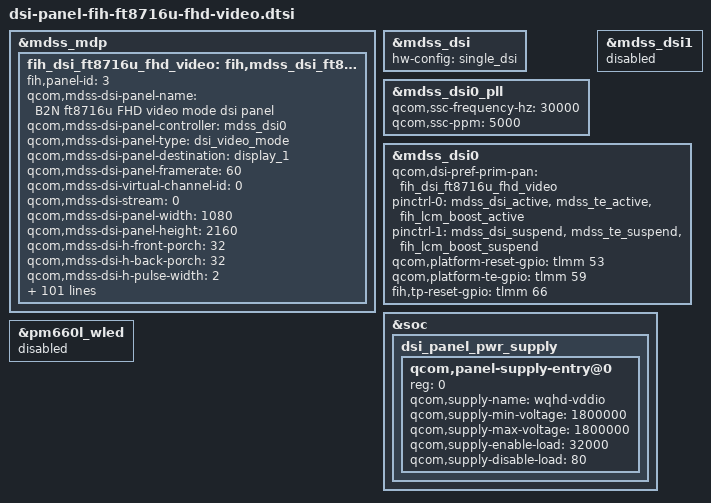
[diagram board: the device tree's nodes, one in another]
/* Copyright (c) 2013, The Linux Foundation. All rights reserved.
 *
 * This program is free software; you can redistribute it and/or modify
 * it under the terms of the GNU General Public License version 2 and
 * only version 2 as published by the Free Software Foundation.
 *
 * This program is distributed in the hope that it will be useful,
 * but WITHOUT ANY WARRANTY; without even the implied warranty of
 * MERCHANTABILITY or FITNESS FOR A PARTICULAR PURPOSE.  See the
 * GNU General Public License for more details.
 */

/*---------------------------------------------------------------------------
 * This file is autogenerated file using gcdb parser. Please do not edit it.
 * Update input XML file to add a new entry or update variable in this file
 * VERSION = "1.0"
 *---------------------------------------------------------------------------*/
&mdss_mdp {
	fih_dsi_ft8716u_fhd_video: fih,mdss_dsi_ft8716u_fhd_video {
		fih,panel-id = <3>;
		qcom,mdss-dsi-panel-name = "B2N ft8716u FHD video mode dsi panel";
		qcom,mdss-dsi-panel-controller = <&mdss_dsi0>;
		qcom,mdss-dsi-panel-type = "dsi_video_mode";
		qcom,mdss-dsi-panel-destination = "display_1";
		qcom,mdss-dsi-panel-framerate = <60>;
		qcom,mdss-dsi-virtual-channel-id = <0>;
		qcom,mdss-dsi-stream = <0>;
		qcom,mdss-dsi-panel-width = <1080>;
		qcom,mdss-dsi-panel-height = <2160>;
		qcom,mdss-dsi-h-front-porch = <32>;
		qcom,mdss-dsi-h-back-porch = <32>;
		qcom,mdss-dsi-h-pulse-width = <2>;
		qcom,mdss-dsi-h-sync-skew = <0>;
		qcom,mdss-dsi-v-front-porch = <16>;
		qcom,mdss-dsi-v-back-porch = <16>;
		qcom,mdss-dsi-v-pulse-width = <2>;
		qcom,mdss-dsi-h-left-border = <0>;
		qcom,mdss-dsi-h-right-border = <0>;
		qcom,mdss-dsi-v-top-border = <0>;
		qcom,mdss-dsi-v-bottom-border = <0>;
		qcom,mdss-dsi-bpp = <24>;
		qcom,mdss-dsi-color-order = "rgb_swap_rgb";
		qcom,mdss-dsi-underflow-color = <0xff>;
		qcom,mdss-dsi-border-color = <0>;
		qcom,mdss-dsi-on-command = [
			39 01 00 00 00 00 02 00 00
			39 01 00 00 00 00 04 FF 87 16 01
			39 01 00 00 00 00 02 00 80
			39 01 00 00 00 00 03 FF 87 16
			39 01 00 00 00 00 02 00 00
			39 01 00 00 00 00 05 2A 00 00 04 37
			39 01 00 00 00 00 02 00 00
			39 01 00 00 00 00 05 2B 00 00 08 6F
			/* Set CABC backlight min & max for UI, ST, MV mode */
			39 01 00 00 00 00 02 00 80
			39 01 00 00 00 00 0B CA 80 CC FF A5 FF 80 FF 00 00 00
			/* Set 53h Dimming frame CAB5 */
			//39 01 00 00 00 00 02 00 B5
			//39 01 00 00 00 00 02 CA 01
			/* CABC G tuning */
			39 01 00 00 00 00 02 00 00
			39 01 00 00 00 00 02 C6 10
			39 01 00 00 00 00 02 00 00
			39 01 00 00 00 00 13 C7 B0 AB BC AA DC AB AA CA BB BC 88 78 56 34 33 33 33 33
			39 01 00 00 00 00 02 00 00
			39 01 00 00 00 00 02 C6 11
			39 01 00 00 00 00 02 00 00
			39 01 00 00 00 00 13 C7 A0 AB AC 9B DB 9B AA AB BB CB 88 88 67 35 33 33 33 33
			39 01 00 00 00 00 02 00 00
			39 01 00 00 00 00 02 C6 12
			39 01 00 00 00 00 02 00 00
			39 01 00 00 00 00 13 C7 A0 AA 9C 9B CB AB A9 AA AB CA 88 88 67 45 44 44 34 33
			39 01 00 00 00 00 02 00 00
			39 01 00 00 00 00 02 C6 13
			39 01 00 00 00 00 02 00 00
			39 01 00 00 00 00 13 C7 A0 9A AB 8B CB AA A9 B9 AA BA 88 88 78 46 44 44 44 44
			39 01 00 00 00 00 02 00 00
			39 01 00 00 00 00 02 C6 14
			39 01 00 00 00 00 02 00 00
			39 01 00 00 00 00 13 C7 90 AA AA 9A CA 9A A9 A9 AA AA 88 88 78 56 55 55 44 44
			39 01 00 00 00 00 02 00 00
			39 01 00 00 00 00 02 C6 15
			39 01 00 00 00 00 02 00 00
			39 01 00 00 00 00 13 C7 90 9A 8B 9B B9 9B 99 A9 B9 A9 88 88 78 56 55 55 55 55
			39 01 00 00 00 00 02 00 00
			39 01 00 00 00 00 02 C6 16
			39 01 00 00 00 00 02 00 00
			39 01 00 00 00 00 13 C7 90 9A 9A 8A C9 9A 89 9A AA A8 88 88 88 67 56 55 55 55
			39 01 00 00 00 00 02 00 00
			39 01 00 00 00 00 02 C6 17
			39 01 00 00 00 00 02 00 00
			39 01 00 00 00 00 13 C7 90 99 9A 8A B9 9A 98 99 A9 99 88 88 88 67 66 66 56 55
			39 01 00 00 00 00 02 00 00
			39 01 00 00 00 00 02 C6 18
			39 01 00 00 00 00 02 00 00
			39 01 00 00 00 00 13 C7 90 99 8A 99 B8 99 89 9A 99 99 88 88 88 67 66 66 66 66
			39 01 00 00 00 00 02 00 00
			39 01 00 00 00 00 02 C6 19
			39 01 00 00 00 00 02 00 00
			39 01 00 00 00 00 13 C7 90 98 8A 99 A8 A9 98 98 99 99 88 88 88 78 67 66 66 66
			39 01 00 00 00 00 02 00 00
			39 01 00 00 00 00 02 C6 1A
			39 01 00 00 00 00 02 00 00
			39 01 00 00 00 00 13 C7 80 99 99 89 A8 99 98 98 99 89 88 88 88 78 77 77 66 66
			39 01 00 00 00 00 02 00 00
			39 01 00 00 00 00 02 C6 1B
			39 01 00 00 00 00 02 00 00
			39 01 00 00 00 00 13 C7 80 98 99 89 98 99 98 98 98 89 88 88 88 78 77 77 77 67
			39 01 00 00 00 00 02 00 00
			39 01 00 00 00 00 02 C6 1C
			39 01 00 00 00 00 02 00 00
			39 01 00 00 00 00 13 C7 80 98 98 89 98 89 89 98 98 89 88 88 88 88 77 77 77 77
			39 01 00 00 00 00 02 00 00
			39 01 00 00 00 00 02 C6 1D
			39 01 00 00 00 00 02 00 00
			39 01 00 00 00 00 13 C7 80 88 89 89 88 99 88 98 98 88 88 88 88 88 88 78 77 77
			39 01 00 00 00 00 02 00 00
			39 01 00 00 00 00 02 C6 1E
			39 01 00 00 00 00 02 00 00
			39 01 00 00 00 00 13 C7 80 88 98 88 88 89 89 88 98 88 88 88 88 88 88 88 78 77
			39 01 00 00 00 00 02 00 00
			39 01 00 00 00 00 02 C6 1F
			39 01 00 00 00 00 02 00 00
			39 01 00 00 00 00 13 C7 80 88 88 88 88 89 88 88 98 87 88 88 88 88 88 88 88 88
			/* Auto Select Curve */
			39 01 00 00 00 00 02 00 00
			39 01 00 00 00 00 02 C6 00
			/* PWM dimming framae = 1 */
			39 01 00 00 00 00 02 00 B5
			39 01 00 00 00 00 02 CA 01
			/* MV-ST-UI CABC Dimming Frame  */
			39 01 00 00 00 00 02 00 A3
			39 01 00 00 00 00 07 CA C8 C8 C8 C8 C8 C8
			/* PWM 10bit */
			39 01 00 00 00 00 02 00 B2
			39 01 00 00 00 00 02 CA 04
			/* for Slpin All gate on */
			//39 01 00 00 00 00 02 00 81
			//39 01 00 00 00 00 0D F3 F8 E1 00 F8 E1 00 00 1C 00 00 1C 00
			15 01 00 00 00 00 02 00 81
			15 01 00 00 00 00 02 F3 F8
			15 01 00 00 00 00 02 00 82
			15 01 00 00 00 00 02 F3 E1
			15 01 00 00 00 00 02 00 83
			15 01 00 00 00 00 02 F3 00
			15 01 00 00 00 00 02 00 84
			15 01 00 00 00 00 02 F3 F8
			15 01 00 00 00 00 02 00 85
			15 01 00 00 00 00 02 F3 E1
			15 01 00 00 00 00 02 00 86
			15 01 00 00 00 00 02 F3 00
			15 01 00 00 00 00 02 00 87
			15 01 00 00 00 00 02 F3 00
			15 01 00 00 00 00 02 00 88
			15 01 00 00 00 00 02 F3 1C
			15 01 00 00 00 00 02 00 89
			15 01 00 00 00 00 02 F3 00
			15 01 00 00 00 00 02 00 8A
			15 01 00 00 00 00 02 F3 00
			15 01 00 00 00 00 02 00 8B
			15 01 00 00 00 00 02 F3 1C
			15 01 00 00 00 00 02 00 8C
			15 01 00 00 00 00 02 F3 00
			/* Slew rate cobtrol */
			39 01 00 00 00 00 02 00 B0
			39 01 00 00 00 00 05 C5 01 00 00 00
			/* CKH EQ */
			39 01 00 00 00 00 02 00 88
			39 01 00 00 00 00 03 C3 33 33
			39 01 00 00 00 00 02 00 98
			39 01 00 00 00 00 03 C3 33 33
			/* CMD 2 Disable CMD for ESD */
			39 01 00 00 00 00 02 00 00
			39 01 00 00 00 00 04 FF 00 00 00
			39 01 00 00 00 00 02 00 80
			39 01 00 00 00 00 03 FF 00 00

			05 01 00 00 78 00 02 11 00
			05 01 00 00 00 00 02 29 00
			15 01 00 00 00 00 02 35 00
			15 01 00 00 00 00 02 53 2C
		];
		qcom,mdss-dsi-off-command = [
			05 01 00 00 0A 00 02 28 00
			05 01 00 00 96 00 02 10 00
		];
		qcom,suspend-ulps-enabled;

		qcom,mdss-dsi-on-command-state = "dsi_lp_mode";
		qcom,mdss-dsi-off-command-state = "dsi_hs_mode";
		qcom,mdss-dsi-h-sync-pulse = <1>;
		qcom,mdss-dsi-traffic-mode = "burst_mode";
		qcom,mdss-dsi-lane-map = "lane_map_0123";
		qcom,mdss-dsi-bllp-eof-power-mode;
		qcom,mdss-dsi-bllp-power-mode;
		qcom,mdss-dsi-lp11-init;
		qcom,mdss-dsi-init-delay-us = <5>;
		qcom,mdss-dsi-lane-0-state;
		qcom,mdss-dsi-lane-1-state;
		qcom,mdss-dsi-lane-2-state;
		qcom,mdss-dsi-lane-3-state;
		qcom,mdss-dsi-t-clk-post = <0x0D>;
		qcom,mdss-dsi-t-clk-pre = <0x30>;
		qcom,mdss-dsi-dma-trigger = "trigger_sw";
		qcom,mdss-dsi-mdp-trigger = "none";
		qcom,mdss-dsi-reset-sequence = <1 1>, <0 1>, <1 10>;

		qcom,mdss-pan-physical-width-dimension = <68>;
		qcom,mdss-pan-physical-height-dimension = <136>;
		qcom,mdss-pan-physical-width-dimension-full = <6804>;
		qcom,mdss-pan-physical-height-dimension-full = <13608>;

		/* SW4-HL-Display-EliminateMostDsiError-00+{_20170216 */
		qcom,mdss-dsi-tx-eot-append;
		/* SW4-HL-Display-EliminateMostDsiError-00+}_20170216 */

		/* SW4-HL-Display-DynamicReadWriteRegister-00+{_20160729 */
		fih,mdss-dsi-write-reg-command = [
			39 01 00 00 00 00 04 FF 78 07 00
		];

		fih,mdss-dsi-write-reg-command-state = "dsi_lp_mode";
		/* SW4-HL-Display-DynamicReadWriteRegister-00+}_20160729 */

		/* B2N - gatycclu - Enable ESD check */
		qcom,esd-check-enabled;
		qcom,mdss-dsi-panel-status-check-mode = "reg_read";
		qcom,mdss-dsi-panel-status-command = [06 01 00 01 00 00 01 0a
			06 01 00 01 00 00 01 0d
			06 01 00 01 00 00 01 ac];
		qcom,mdss-dsi-panel-status-command-state = "dsi_hs_mode";
		qcom,mdss-dsi-panel-status-value = <0x9c>,<0x00>,<0x00>;
		qcom,mdss-dsi-panel-on-check-value = <0x9c>,<0x00>,<0x00>;
		qcom,mdss-dsi-panel-status-read-length = <1>,<1>,<1>;
		qcom,mdss-dsi-panel-max-error-count = <3>;
		/* end - B2N - Enable ESD check */
		qcom,mdss-dsi-cabc-off-command = [
			39 01 00 00 00 00 02 55 02
		];

		qcom,mdss-dsi-cabc-ui-command = [
			39 01 00 00 00 00 02 55 01
		];

		qcom,mdss-dsi-cabc-still-command = [
			39 01 00 00 00 00 02 55 02
		];

		qcom,mdss-dsi-cabc-moving-command = [
			39 01 00 00 00 00 02 55 03
		];

		qcom,mdss-dsi-cabc-off-command-state = "dsi_hs_mode";
		qcom,mdss-dsi-cabc-ui-command-state = "dsi_hs_mode";
		qcom,mdss-dsi-cabc-still-command-state = "dsi_hs_mode";
		qcom,mdss-dsi-cabc-moving-command-state = "dsi_hs_mode";

		qcom,mdss-dsi-cabc-off-command-BeforeInit = [
			39 01 00 00 00 00 02 55 02
		];

		qcom,mdss-dsi-cabc-ui-command-BeforeInit = [
			39 01 00 00 00 00 02 55 01
		];

		qcom,mdss-dsi-cabc-still-command-BeforeInit = [
			39 01 00 00 00 00 02 55 02
		];

		qcom,mdss-dsi-cabc-moving-command-BeforeInit = [
			39 01 00 00 00 00 02 55 03
		];

		qcom,mdss-dsi-cabc-off-command-BeforeInit-state = "dsi_lp_mode";
		qcom,mdss-dsi-cabc-ui-command-BeforeInit-state = "dsi_lp_mode";
		qcom,mdss-dsi-cabc-still-command-BeforeInit-state = "dsi_lp_mode";
		qcom,mdss-dsi-cabc-moving-command-BeforeInit-state = "dsi_lp_mode";

		fih,default-cabc-mode = <2>;
	};
};

&fih_dsi_ft8716u_fhd_video {
	qcom,mdss-dsi-panel-timings-phy-v2 = [
		24 1F 08 09 05 03 04 a0
		24 1F 08 09 05 03 04 a0
		24 1F 08 09 05 03 04 a0
		24 1F 08 09 05 03 04 a0
		24 1F 08 09 05 03 04 a0
	];
	//qcom,mdss-dsi-bl-pmic-control-type = "bl_ctrl_wled";
	qcom,mdss-dsi-bl-pmic-control-type = "bl_ctrl_dcs";
	qcom,mdss-dsi-bl-min-level = <1>;
	qcom,mdss-dsi-bl-max-level = <255>;
	qcom,panel-supply-entries = <&dsi_panel_pwr_supply>;
};

&mdss_dsi {
	hw-config = "single_dsi";
};

&mdss_dsi0_pll {
	qcom,ssc-frequency-hz = <30000>;
	qcom,ssc-ppm = <5000>;
};

&mdss_dsi1 {
	status = "disabled";
};


&mdss_dsi0 {
	qcom,dsi-pref-prim-pan = <&fih_dsi_ft8716u_fhd_video>;
	pinctrl-names = "mdss_default", "mdss_sleep";
	pinctrl-0 = <&mdss_dsi_active &mdss_te_active &fih_lcm_boost_active>;
	pinctrl-1 = <&mdss_dsi_suspend &mdss_te_suspend &fih_lcm_boost_suspend>;
	qcom,platform-reset-gpio = <&tlmm 53 0>;
	qcom,platform-te-gpio = <&tlmm 59 0>;
        fih,tp-reset-gpio = <&tlmm 66 0>;
};

&soc {
	/delete-node/dsi_panel_pwr_supply;

	dsi_panel_pwr_supply: dsi_panel_pwr_supply {
		#address-cells = <1>;
		#size-cells = <0>;

		/* PM660 L11 */
		qcom,panel-supply-entry@0 {
			reg = <0>;
			qcom,supply-name = "wqhd-vddio";
			qcom,supply-min-voltage = <1800000>;
			qcom,supply-max-voltage = <1800000>;
			qcom,supply-enable-load = <32000>;
			qcom,supply-disable-load = <80>;
		};
	};
};

&pm660l_wled {
	status = "disabled";
};
